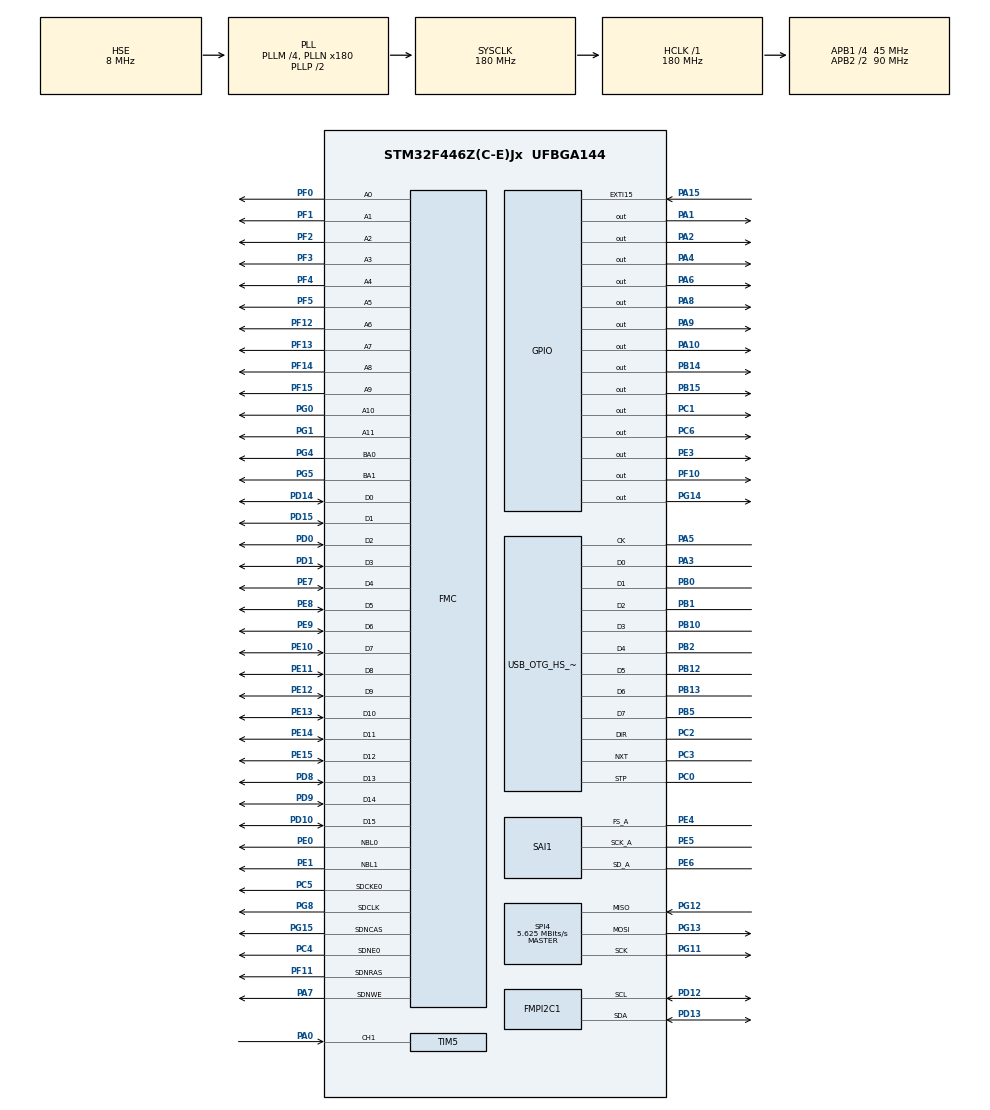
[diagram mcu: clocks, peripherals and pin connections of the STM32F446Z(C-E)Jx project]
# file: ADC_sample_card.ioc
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Dma.Request0=SAI1_A
Dma.SAI1_A.0.Direction=DMA_PERIPH_TO_MEMORY
Dma.SAI1_A.0.FIFOMode=DMA_FIFOMODE_DISABLE
Dma.SAI1_A.0.Instance=DMA2_Stream1
Dma.SAI1_A.0.MemDataAlignment=DMA_MDATAALIGN_WORD
Dma.SAI1_A.0.MemInc=DMA_MINC_ENABLE
Dma.SAI1_A.0.Mode=DMA_CIRCULAR
Dma.SAI1_A.0.PeriphDataAlignment=DMA_PDATAALIGN_WORD
Dma.SAI1_A.0.PeriphInc=DMA_PINC_DISABLE
Dma.SAI1_A.0.Priority=DMA_PRIORITY_LOW
FMC.CASLatency2=FMC_SDRAM_CAS_LATENCY_3
FMC.ExitSelfRefreshDelay2=7
FMC.LoadToActiveDelay2=2
FMC.RCDDelay2=2
FMC.RPDelay1=2
FMC.RPDelay2=2
FMC.ReadPipeDelay1=FMC_SDRAM_RPIPE_DELAY_1
FMC.ReadPipeDelay2=FMC_SDRAM_RPIPE_DELAY_1
FMC.RowCycleDelay1=7
FMC.RowCycleDelay2=7
FMC.SDClockPeriod1=FMC_SDRAM_CLOCK_PERIOD_3
FMC.SDClockPeriod2=FMC_SDRAM_CLOCK_PERIOD_3
FMC.SelfRefreshTime2=4
FMC.WriteRecoveryTime2=3
FMPI2C1.FMPI2C_Coeff_DF=5
FMPI2C1.Speed=100
FMPI2C1.Timing=0x20303955
FREERTOS.BinarySemaphores01=CommandSem,Dynamic,NULL
FREERTOS.Queues01=QueueTx,2,uint16_t,0,Dynamic,NULL,NULL
FREERTOS.Tasks01=defaultTask,0,128,StartDefaultTask,Default,NULL,Dynamic,NULL,NULL;usbTask,-3,128,UsbTask,Default,NULL,Dynamic,NULL,NULL
FREERTOS.configTOTAL_HEAP_SIZE=4096
Mcu.Family=STM32F4
Mcu.Name=STM32F446Z(C-E)Jx
Mcu.Package=UFBGA144
NVIC.DMA2_Stream1_IRQn=true\:5\:0\:false\:false\:true\:true\:false\:true
NVIC.EXTI15_10_IRQn=true\:5\:0\:false\:false\:true\:true\:true\:true
NVIC.OTG_HS_IRQn=true\:5\:0\:false\:false\:true\:true\:false\:true
NVIC.PriorityGroup=NVIC_PRIORITYGROUP_4
NVIC.SAI1_IRQn=true\:5\:0\:false\:false\:true\:true\:true\:true
NVIC.TIM6_DAC_IRQn=true\:0\:0\:false\:false\:true\:false\:false\:true
NVIC.TimeBase=TIM6_DAC_IRQn
NVIC.TimeBaseIP=TIM6
PA0-WKUP.Signal=S_TIM5_CH1
PA1.Signal=GPIO_Output
PA10.Signal=GPIO_Output
PA13.Mode=Serial_Wire
PA13.Signal=SYS_JTMS-SWDIO
PA14.Mode=Serial_Wire
PA14.Signal=SYS_JTCK-SWCLK
PA15.GPIO_ModeDefaultEXTI=GPIO_MODE_IT_RISING
PA15.Signal=GPXTI15
PA2.Signal=GPIO_Output
PA3.Mode=Device_HS
PA3.Signal=USB_OTG_HS_ULPI_D0
PA4.Signal=GPIO_Output
PA5.Mode=Device_HS
PA5.Signal=USB_OTG_HS_ULPI_CK
PA6.Signal=GPIO_Output
PA7.Signal=FMC_SDNWE
PA8.Signal=GPIO_Output
PA9.Signal=GPIO_Output
PB0.Mode=Device_HS
PB0.Signal=USB_OTG_HS_ULPI_D1
PB1.Mode=Device_HS
PB1.Signal=USB_OTG_HS_ULPI_D2
PB10.Mode=Device_HS
PB10.Signal=USB_OTG_HS_ULPI_D3
PB12.Mode=Device_HS
PB12.Signal=USB_OTG_HS_ULPI_D5
PB13.Mode=Device_HS
PB13.Signal=USB_OTG_HS_ULPI_D6
PB14.Signal=GPIO_Output
PB15.PinState=GPIO_PIN_SET
PB15.Signal=GPIO_Output
PB2.Mode=Device_HS
PB2.Signal=USB_OTG_HS_ULPI_D4
PB5.Mode=Device_HS
PB5.Signal=USB_OTG_HS_ULPI_D7
PC0.Mode=Device_HS
PC0.Signal=USB_OTG_HS_ULPI_STP
PC1.Signal=GPIO_Output
PC2.Mode=Device_HS
PC2.Signal=USB_OTG_HS_ULPI_DIR
PC3.Mode=Device_HS
PC3.Signal=USB_OTG_HS_ULPI_NXT
PC4.Mode=SdramChipSelect1_2
PC4.Signal=FMC_SDNE0
PC5.Mode=SdramChipSelect1_2
PC5.Signal=FMC_SDCKE0
PC6.PinState=GPIO_PIN_SET
PC6.Signal=GPIO_Output
PD0.Signal=FMC_D2_DA2
PD1.Signal=FMC_D3_DA3
PD10.Signal=FMC_D15_DA15
PD12.Mode=I2C
PD12.Signal=FMPI2C1_SCL
PD13.Mode=I2C
PD13.Signal=FMPI2C1_SDA
PD14.Signal=FMC_D0_DA0
PD15.Signal=FMC_D1_DA1
PD8.Signal=FMC_D13_DA13
PD9.Signal=FMC_D14_DA14
PE0.Signal=FMC_NBL0
PE1.Signal=FMC_NBL1
PE10.Signal=FMC_D7_DA7
PE11.Signal=FMC_D8_DA8
PE12.Signal=FMC_D9_DA9
PE13.Signal=FMC_D10_DA10
PE14.Signal=FMC_D11_DA11
PE15.Signal=FMC_D12_DA12
PE3.PinState=GPIO_PIN_SET
PE3.Signal=GPIO_Output
PE4.GPIO_Speed=GPIO_SPEED_FREQ_HIGH
PE4.Mode=SAI_A_AsyncSlave
PE4.Signal=SAI1_FS_A
PE5.GPIO_Speed=GPIO_SPEED_FREQ_HIGH
PE5.Mode=SAI_A_AsyncSlave
PE5.Signal=SAI1_SCK_A
PE6.GPIO_Speed=GPIO_SPEED_FREQ_HIGH
PE6.Mode=SAI_A_AsyncSlave
PE6.Signal=SAI1_SD_A
PE7.Signal=FMC_D4_DA4
PE8.Signal=FMC_D5_DA5
PE9.Signal=FMC_D6_DA6
PF0.Signal=FMC_A0
PF1.Signal=FMC_A1
PF10.GPIO_ModeDefaultOutputPP=GPIO_MODE_OUTPUT_PP
PF10.GPIO_PuPd=GPIO_NOPULL
PF10.GPIO_Speed=GPIO_SPEED_FREQ_LOW
PF10.PinState=GPIO_PIN_RESET
PF10.Signal=GPIO_Output
PF11.Signal=FMC_SDNRAS
PF12.Signal=FMC_A6
PF13.Signal=FMC_A7
PF14.Signal=FMC_A8
PF15.Signal=FMC_A9
PF2.Signal=FMC_A2
PF3.Signal=FMC_A3
PF4.Signal=FMC_A4
PF5.Signal=FMC_A5
PG0.Signal=FMC_A10
PG1.Signal=FMC_A11
PG11.Mode=Full_Duplex_Master
PG11.Signal=SPI4_SCK
PG12.Mode=Full_Duplex_Master
PG12.Signal=SPI4_MISO
PG13.Mode=Full_Duplex_Master
PG13.Signal=SPI4_MOSI
PG14.PinState=GPIO_PIN_SET
PG14.Signal=GPIO_Output
PG15.Signal=FMC_SDNCAS
PG4.Signal=FMC_A14_BA0
PG5.Signal=FMC_A15_BA1
PG8.Signal=FMC_SDCLK
PH0-OSC_IN.Mode=HSE-External-Oscillator
PH0-OSC_IN.Signal=RCC_OSC_IN
PH1-OSC_OUT.Mode=HSE-External-Oscillator
PH1-OSC_OUT.Signal=RCC_OSC_OUT
ProjectManager.HeapSize=0x600
ProjectManager.StackSize=0x900
ProjectManager.TargetToolchain=MDK-ARM V5
RCC.AHBFreq_Value=180000000
RCC.APB1CLKDivider=RCC_HCLK_DIV4
RCC.APB1Freq_Value=45000000
RCC.APB1TimFreq_Value=90000000
RCC.APB2CLKDivider=RCC_HCLK_DIV2
RCC.APB2Freq_Value=90000000
RCC.APB2TimFreq_Value=180000000
RCC.CortexFreq_Value=180000000
RCC.HCLKFreq_Value=180000000
RCC.HSE_VALUE=8000000
RCC.PLLM=4
RCC.PLLN=180
RCC.PLLSAIM=4
RCC.PLLSAIN=50
RCC.PLLSourceVirtual=RCC_PLLSOURCE_HSE
RCC.SYSCLKFreq_VALUE=180000000
RCC.SYSCLKSource=RCC_SYSCLKSOURCE_PLLCLK
RCC.USBFreq_Value=180000000
RCC.VCOOutputFreq_Value=360000000
SAI1.ClockStrobing-SAI_A_AsyncSlave=SAI_CLOCKSTROBING_RISINGEDGE
SAI1.DataSize-SAI_A_AsyncSlave=SAI_DATASIZE_32
SAI1.FIFOThreshold-SAI_A_AsyncSlave=SAI_FIFOTHRESHOLD_FULL
SAI1.FSOffset-SAI_A_AsyncSlave=SAI_FS_FIRSTBIT
SAI1.FrameLength-SAI_A_AsyncSlave=128
SAI1.Instance-SAI_A_AsyncSlave=SAI$Index_Block_A
SAI1.OutputDrive-SAI_A_AsyncSlave=SAI_OUTPUTDRIVE_DISABLE
SAI1.Protocol-SAI_A_AsyncSlave=SAI_FREE_PROTOCOL
SAI1.SlotActive-SAI_A_AsyncSlave=0x0000FFFF
SAI1.SlotNumber-SAI_A_AsyncSlave=4
SAI1.TriState-SAI_A_AsyncSlave=SAI_OUTPUT_RELEASED
SAI1.VirtualMode-SAI_A_AsyncSlave=VM_SLAVE
SAI1.VirtualSlotActive-SAI_A_AsyncSlave=SAI_SLOTACTIVE_ALL
SAI1.VirtualSlotActive0-SAI_A_AsyncSlave=false
SH.FMC_A0.0=FMC_A0,12b-sda2
SH.FMC_A1.0=FMC_A1,12b-sda2
SH.FMC_A10.0=FMC_A10,12b-sda2
SH.FMC_A11.0=FMC_A11,12b-sda2
SH.FMC_A14_BA0.0=FMC_BA0,FourSdramBanks2
SH.FMC_A15_BA1.0=FMC_BA1,FourSdramBanks2
SH.FMC_A2.0=FMC_A2,12b-sda2
SH.FMC_A3.0=FMC_A3,12b-sda2
SH.FMC_A4.0=FMC_A4,12b-sda2
SH.FMC_A5.0=FMC_A5,12b-sda2
SH.FMC_A6.0=FMC_A6,12b-sda2
SH.FMC_A7.0=FMC_A7,12b-sda2
SH.FMC_A8.0=FMC_A8,12b-sda2
SH.FMC_A9.0=FMC_A9,12b-sda2
SH.FMC_D0_DA0.0=FMC_D0,sd-16b-d2
SH.FMC_D10_DA10.0=FMC_D10,sd-16b-d2
SH.FMC_D11_DA11.0=FMC_D11,sd-16b-d2
SH.FMC_D12_DA12.0=FMC_D12,sd-16b-d2
SH.FMC_D13_DA13.0=FMC_D13,sd-16b-d2
SH.FMC_D14_DA14.0=FMC_D14,sd-16b-d2
SH.FMC_D15_DA15.0=FMC_D15,sd-16b-d2
SH.FMC_D1_DA1.0=FMC_D1,sd-16b-d2
SH.FMC_D2_DA2.0=FMC_D2,sd-16b-d2
SH.FMC_D3_DA3.0=FMC_D3,sd-16b-d2
SH.FMC_D4_DA4.0=FMC_D4,sd-16b-d2
SH.FMC_D5_DA5.0=FMC_D5,sd-16b-d2
SH.FMC_D6_DA6.0=FMC_D6,sd-16b-d2
SH.FMC_D7_DA7.0=FMC_D7,sd-16b-d2
SH.FMC_D8_DA8.0=FMC_D8,sd-16b-d2
SH.FMC_D9_DA9.0=FMC_D9,sd-16b-d2
SH.FMC_NBL0.0=FMC_NBL0,Sd2ByteEnable2
SH.FMC_NBL1.0=FMC_NBL1,Sd2ByteEnable2
SH.FMC_SDCLK.0=FMC_SDCLK,12b-sda2
SH.FMC_SDNCAS.0=FMC_SDNCAS,12b-sda2
SH.FMC_SDNRAS.0=FMC_SDNRAS,12b-sda2
SH.FMC_SDNWE.0=FMC_SDNWE,12b-sda2
SH.S_TIM5_CH1.0=TIM5_CH1,TriggerSource_TI1FP1
SPI4.BaudRatePrescaler=SPI_BAUDRATEPRESCALER_16
SPI4.CalculateBaudRate=5.625 MBits/s
SPI4.DataSize=SPI_DATASIZE_8BIT
SPI4.Direction=SPI_DIRECTION_2LINES
SPI4.Mode=SPI_MODE_MASTER
SPI4.VirtualType=VM_MASTER
TIM5.Period=65535
TIM5.Slave_TriggerFilter=1
USB_DEVICE.CLASS_NAME_HS=CDC
USB_DEVICE.VirtualMode-CDC_HS=Cdc
USB_DEVICE.VirtualModeHS=Cdc_HS
USB_OTG_HS.DeviceSpeed-Device_HS=PCD_SPEED_HIGH
USB_OTG_HS.VirtualMode-Device_HS=Device_HS
USB_OTG_HS.dma_enable-Device_HS=DISABLE
VP_FREERTOS_VS_CMSIS_V1.Mode=CMSIS_V1
VP_SYS_VS_tim6.Mode=TIM6
VP_TIM5_VS_ControllerModeClock.Mode=Clock Mode
VP_USB_DEVICE_VS_USB_DEVICE_CDC_HS.Mode=CDC_HS
board=custom

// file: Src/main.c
/* USER CODE BEGIN Header */
/**
  ******************************************************************************
  * @file           : main.c
  * @brief          : Main program body
  ******************************************************************************
  * @attention
  *
  * <h2><center>&copy; Copyright (c) 2019 STMicroelectronics.
  * All rights reserved.</center></h2>
  *
  * This software component is licensed by ST under Ultimate Liberty license
  * SLA0044, the "License"; You may not use this file except in compliance with
  * the License. You may obtain a copy of the License at:
  *                             www.st.com/SLA0044
  *
  ******************************************************************************
  */
/* USER CODE END Header */

#include "main.h"
#include "cmsis_os.h"
#include "usb_device.h"

/* USER CODE BEGIN Includes */
#include "CDCEL913.h"
#include "ad7768.h"
#include "command.h"
#include "usbd_cdc_if.h"
#include "sdram.h"
/* USER CODE END Includes */

FMPI2C_HandleTypeDef hfmpi2c1;

SAI_HandleTypeDef hsai_BlockA1;
DMA_HandleTypeDef hdma_sai1_a;

SPI_HandleTypeDef hspi4;

TIM_HandleTypeDef htim5;

SDRAM_HandleTypeDef hsdram2;

osThreadId defaultTaskHandle;
osThreadId usbTaskHandle;
osMessageQId QueueTxHandle;
osSemaphoreId CommandSemHandle;

void SystemClock_Config(void);
static void MX_GPIO_Init(void);
static void MX_DMA_Init(void);
static void MX_FMPI2C1_Init(void);
static void MX_SPI4_Init(void);
static void MX_SAI1_Init(void);
static void MX_FMC_Init(void);
static void MX_TIM5_Init(void);
void StartDefaultTask(void const * argument);
void UsbTask(void const * argument);

/* USER CODE BEGIN PFP */
FMC_SDRAM_CommandTypeDef command;

uint16_t digital_cnt = 0;
uint32_t digital_clk[256];
/* USER CODE END PFP */

int main(void)
{

  /* MCU Configuration--------------------------------------------------------*/

  /* Reset of all peripherals, Initializes the Flash interface and the Systick. */
  HAL_Init();

  /* Configure the system clock */
  SystemClock_Config();

  /* Initialize all configured peripherals */
  MX_GPIO_Init();
  MX_DMA_Init();
  MX_FMPI2C1_Init();
  MX_SPI4_Init();
  MX_SAI1_Init();
  MX_FMC_Init();
  MX_TIM5_Init();
  /* USER CODE BEGIN 2 */
	SDRAM_Initialization_Sequence(&hsdram2, &command);
  /* USER CODE END 2 */

  /* Create the semaphores(s) */
  /* definition and creation of CommandSem */
  osSemaphoreDef(CommandSem);
  CommandSemHandle = osSemaphoreCreate(osSemaphore(CommandSem), 1);

  /* Create the queue(s) */
  /* definition and creation of QueueTx */
  osMessageQDef(QueueTx, 2, uint16_t);
  QueueTxHandle = osMessageCreate(osMessageQ(QueueTx), NULL);

  /* Create the thread(s) */
  /* definition and creation of defaultTask */
  osThreadDef(defaultTask, StartDefaultTask, osPriorityNormal, 0, 128);
  defaultTaskHandle = osThreadCreate(osThread(defaultTask), NULL);

  /* definition and creation of usbTask */
  osThreadDef(usbTask, UsbTask, osPriorityIdle, 0, 128);
  usbTaskHandle = osThreadCreate(osThread(usbTask), NULL);

  /* Start scheduler */
  osKernelStart();

  /* We should never get here as control is now taken by the scheduler */
  /* Infinite loop */
  while (1)
  {

  }
}

void SystemClock_Config(void)
{
  RCC_OscInitTypeDef RCC_OscInitStruct = {0};
  RCC_ClkInitTypeDef RCC_ClkInitStruct = {0};
  RCC_PeriphCLKInitTypeDef PeriphClkInitStruct = {0};

  /** Configure the main internal regulator output voltage
  */
  __HAL_RCC_PWR_CLK_ENABLE();
  __HAL_PWR_VOLTAGESCALING_CONFIG(PWR_REGULATOR_VOLTAGE_SCALE1);
  /** Initializes the CPU, AHB and APB busses clocks
  */
  RCC_OscInitStruct.OscillatorType = RCC_OSCILLATORTYPE_HSE;
  RCC_OscInitStruct.HSEState = RCC_HSE_ON;
  RCC_OscInitStruct.PLL.PLLState = RCC_PLL_ON;
  RCC_OscInitStruct.PLL.PLLSource = RCC_PLLSOURCE_HSE;
  RCC_OscInitStruct.PLL.PLLM = 4;
  RCC_OscInitStruct.PLL.PLLN = 180;
  RCC_OscInitStruct.PLL.PLLP = RCC_PLLP_DIV2;
  RCC_OscInitStruct.PLL.PLLQ = 2;
  RCC_OscInitStruct.PLL.PLLR = 2;
  if (HAL_RCC_OscConfig(&RCC_OscInitStruct) != HAL_OK)
  {
    Error_Handler();
  }
  /** Activate the Over-Drive mode
  */
  if (HAL_PWREx_EnableOverDrive() != HAL_OK)
  {
    Error_Handler();
  }
  /** Initializes the CPU, AHB and APB busses clocks
  */
  RCC_ClkInitStruct.ClockType = RCC_CLOCKTYPE_HCLK|RCC_CLOCKTYPE_SYSCLK
                              |RCC_CLOCKTYPE_PCLK1|RCC_CLOCKTYPE_PCLK2;
  RCC_ClkInitStruct.SYSCLKSource = RCC_SYSCLKSOURCE_PLLCLK;
  RCC_ClkInitStruct.AHBCLKDivider = RCC_SYSCLK_DIV1;
  RCC_ClkInitStruct.APB1CLKDivider = RCC_HCLK_DIV4;
  RCC_ClkInitStruct.APB2CLKDivider = RCC_HCLK_DIV2;

  if (HAL_RCC_ClockConfig(&RCC_ClkInitStruct, FLASH_LATENCY_5) != HAL_OK)
  {
    Error_Handler();
  }
  PeriphClkInitStruct.PeriphClockSelection = RCC_PERIPHCLK_SAI1|RCC_PERIPHCLK_FMPI2C1;
  PeriphClkInitStruct.PLLSAI.PLLSAIM = 4;
  PeriphClkInitStruct.PLLSAI.PLLSAIN = 50;
  PeriphClkInitStruct.PLLSAI.PLLSAIQ = 2;
  PeriphClkInitStruct.PLLSAI.PLLSAIP = RCC_PLLSAIP_DIV2;
  PeriphClkInitStruct.PLLSAIDivQ = 1;
  PeriphClkInitStruct.Sai1ClockSelection = RCC_SAI1CLKSOURCE_PLLSAI;
  PeriphClkInitStruct.Fmpi2c1ClockSelection = RCC_FMPI2C1CLKSOURCE_APB;
  if (HAL_RCCEx_PeriphCLKConfig(&PeriphClkInitStruct) != HAL_OK)
  {
    Error_Handler();
  }
}

static void MX_FMPI2C1_Init(void)
{

  hfmpi2c1.Instance = FMPI2C1;
  hfmpi2c1.Init.Timing = 0x20303955;
  hfmpi2c1.Init.OwnAddress1 = 0;
  hfmpi2c1.Init.AddressingMode = FMPI2C_ADDRESSINGMODE_7BIT;
  hfmpi2c1.Init.DualAddressMode = FMPI2C_DUALADDRESS_DISABLE;
  hfmpi2c1.Init.OwnAddress2 = 0;
  hfmpi2c1.Init.OwnAddress2Masks = FMPI2C_OA2_NOMASK;
  hfmpi2c1.Init.GeneralCallMode = FMPI2C_GENERALCALL_DISABLE;
  hfmpi2c1.Init.NoStretchMode = FMPI2C_NOSTRETCH_DISABLE;
  if (HAL_FMPI2C_Init(&hfmpi2c1) != HAL_OK)
  {
    Error_Handler();
  }
  /** Configure Analogue filter
  */
  if (HAL_FMPI2CEx_ConfigAnalogFilter(&hfmpi2c1, FMPI2C_ANALOGFILTER_ENABLE) != HAL_OK)
  {
    Error_Handler();
  }

}

static void MX_SAI1_Init(void)
{

  hsai_BlockA1.Instance = SAI1_Block_A;
  hsai_BlockA1.Init.Protocol = SAI_FREE_PROTOCOL;
  hsai_BlockA1.Init.AudioMode = SAI_MODESLAVE_RX;
  hsai_BlockA1.Init.DataSize = SAI_DATASIZE_32;
  hsai_BlockA1.Init.FirstBit = SAI_FIRSTBIT_MSB;
  hsai_BlockA1.Init.ClockStrobing = SAI_CLOCKSTROBING_RISINGEDGE;
  hsai_BlockA1.Init.Synchro = SAI_ASYNCHRONOUS;
  hsai_BlockA1.Init.OutputDrive = SAI_OUTPUTDRIVE_DISABLE;
  hsai_BlockA1.Init.FIFOThreshold = SAI_FIFOTHRESHOLD_FULL;
  hsai_BlockA1.Init.SynchroExt = SAI_SYNCEXT_DISABLE;
  hsai_BlockA1.Init.MonoStereoMode = SAI_STEREOMODE;
  hsai_BlockA1.Init.CompandingMode = SAI_NOCOMPANDING;
  hsai_BlockA1.Init.TriState = SAI_OUTPUT_RELEASED;
  hsai_BlockA1.FrameInit.FrameLength = 128;
  hsai_BlockA1.FrameInit.ActiveFrameLength = 1;
  hsai_BlockA1.FrameInit.FSDefinition = SAI_FS_STARTFRAME;
  hsai_BlockA1.FrameInit.FSPolarity = SAI_FS_ACTIVE_LOW;
  hsai_BlockA1.FrameInit.FSOffset = SAI_FS_FIRSTBIT;
  hsai_BlockA1.SlotInit.FirstBitOffset = 0;
  hsai_BlockA1.SlotInit.SlotSize = SAI_SLOTSIZE_DATASIZE;
  hsai_BlockA1.SlotInit.SlotNumber = 4;
  hsai_BlockA1.SlotInit.SlotActive = 0x0000FFFF;
  if (HAL_SAI_Init(&hsai_BlockA1) != HAL_OK)
  {
    Error_Handler();
  }

}

static void MX_SPI4_Init(void)
{

  /* SPI4 parameter configuration*/
  hspi4.Instance = SPI4;
  hspi4.Init.Mode = SPI_MODE_MASTER;
  hspi4.Init.Direction = SPI_DIRECTION_2LINES;
  hspi4.Init.DataSize = SPI_DATASIZE_8BIT;
  hspi4.Init.CLKPolarity = SPI_POLARITY_LOW;
  hspi4.Init.CLKPhase = SPI_PHASE_1EDGE;
  hspi4.Init.NSS = SPI_NSS_SOFT;
  hspi4.Init.BaudRatePrescaler = SPI_BAUDRATEPRESCALER_16;
  hspi4.Init.FirstBit = SPI_FIRSTBIT_MSB;
  hspi4.Init.TIMode = SPI_TIMODE_DISABLE;
  hspi4.Init.CRCCalculation = SPI_CRCCALCULATION_DISABLE;
  hspi4.Init.CRCPolynomial = 10;
  if (HAL_SPI_Init(&hspi4) != HAL_OK)
  {
    Error_Handler();
  }

}

static void MX_TIM5_Init(void)
{

  TIM_SlaveConfigTypeDef sSlaveConfig = {0};
  TIM_MasterConfigTypeDef sMasterConfig = {0};

  htim5.Instance = TIM5;
  htim5.Init.Prescaler = 0;
  htim5.Init.CounterMode = TIM_COUNTERMODE_UP;
  htim5.Init.Period = 65535;
  htim5.Init.ClockDivision = TIM_CLOCKDIVISION_DIV1;
  htim5.Init.AutoReloadPreload = TIM_AUTORELOAD_PRELOAD_DISABLE;
  if (HAL_TIM_Base_Init(&htim5) != HAL_OK)
  {
    Error_Handler();
  }
  sSlaveConfig.SlaveMode = TIM_SLAVEMODE_EXTERNAL1;
  sSlaveConfig.InputTrigger = TIM_TS_TI1FP1;
  sSlaveConfig.TriggerPolarity = TIM_TRIGGERPOLARITY_RISING;
  sSlaveConfig.TriggerFilter = 1;
  if (HAL_TIM_SlaveConfigSynchro(&htim5, &sSlaveConfig) != HAL_OK)
  {
    Error_Handler();
  }
  sMasterConfig.MasterOutputTrigger = TIM_TRGO_RESET;
  sMasterConfig.MasterSlaveMode = TIM_MASTERSLAVEMODE_DISABLE;
  if (HAL_TIMEx_MasterConfigSynchronization(&htim5, &sMasterConfig) != HAL_OK)
  {
    Error_Handler();
  }

}

static void MX_DMA_Init(void)
{

  /* DMA controller clock enable */
  __HAL_RCC_DMA2_CLK_ENABLE();

  /* DMA interrupt init */
  /* DMA2_Stream1_IRQn interrupt configuration */
  HAL_NVIC_SetPriority(DMA2_Stream1_IRQn, 5, 0);
  HAL_NVIC_EnableIRQ(DMA2_Stream1_IRQn);

}

/* FMC initialization function */
static void MX_FMC_Init(void)
{

  FMC_SDRAM_TimingTypeDef SdramTiming = {0};

  /** Perform the SDRAM2 memory initialization sequence
  */
  hsdram2.Instance = FMC_SDRAM_DEVICE;
  /* hsdram2.Init */
  hsdram2.Init.SDBank = FMC_SDRAM_BANK2;
  hsdram2.Init.ColumnBitsNumber = FMC_SDRAM_COLUMN_BITS_NUM_8;
  hsdram2.Init.RowBitsNumber = FMC_SDRAM_ROW_BITS_NUM_12;
  hsdram2.Init.MemoryDataWidth = FMC_SDRAM_MEM_BUS_WIDTH_16;
  hsdram2.Init.InternalBankNumber = FMC_SDRAM_INTERN_BANKS_NUM_4;
  hsdram2.Init.CASLatency = FMC_SDRAM_CAS_LATENCY_3;
  hsdram2.Init.WriteProtection = FMC_SDRAM_WRITE_PROTECTION_DISABLE;
  hsdram2.Init.SDClockPeriod = FMC_SDRAM_CLOCK_PERIOD_3;
  hsdram2.Init.ReadBurst = FMC_SDRAM_RBURST_DISABLE;
  hsdram2.Init.ReadPipeDelay = FMC_SDRAM_RPIPE_DELAY_1;
  /* SdramTiming */
  SdramTiming.LoadToActiveDelay = 2;
  SdramTiming.ExitSelfRefreshDelay = 7;
  SdramTiming.SelfRefreshTime = 4;
  SdramTiming.RowCycleDelay = 7;
  SdramTiming.WriteRecoveryTime = 3;
  SdramTiming.RPDelay = 2;
  SdramTiming.RCDDelay = 2;

  if (HAL_SDRAM_Init(&hsdram2, &SdramTiming) != HAL_OK)
  {
    Error_Handler( );
  }

}

static void MX_GPIO_Init(void)
{
  GPIO_InitTypeDef GPIO_InitStruct = {0};

  /* GPIO Ports Clock Enable */
  __HAL_RCC_GPIOE_CLK_ENABLE();
  __HAL_RCC_GPIOA_CLK_ENABLE();
  __HAL_RCC_GPIOB_CLK_ENABLE();
  __HAL_RCC_GPIOG_CLK_ENABLE();
  __HAL_RCC_GPIOF_CLK_ENABLE();
  __HAL_RCC_GPIOH_CLK_ENABLE();
  __HAL_RCC_GPIOD_CLK_ENABLE();
  __HAL_RCC_GPIOC_CLK_ENABLE();

  /*Configure GPIO pin Output Level */
  HAL_GPIO_WritePin(GPIOE, GPIO_PIN_3, GPIO_PIN_SET);

  /*Configure GPIO pin Output Level */
  HAL_GPIO_WritePin(GPIOG, GPIO_PIN_14, GPIO_PIN_SET);

  /*Configure GPIO pin Output Level */
  HAL_GPIO_WritePin(GPIOA, GPIO_PIN_10|GPIO_PIN_9|GPIO_PIN_8|GPIO_PIN_4
                          |GPIO_PIN_1|GPIO_PIN_2|GPIO_PIN_6, GPIO_PIN_RESET);

  /*Configure GPIO pin Output Level */
  HAL_GPIO_WritePin(GPIOF, GPIO_PIN_10, GPIO_PIN_RESET);

  /*Configure GPIO pin Output Level */
  HAL_GPIO_WritePin(GPIOC, GPIO_PIN_6, GPIO_PIN_SET);

  /*Configure GPIO pin Output Level */
  HAL_GPIO_WritePin(GPIOC, GPIO_PIN_1, GPIO_PIN_RESET);

  /*Configure GPIO pin Output Level */
  HAL_GPIO_WritePin(GPIOB, GPIO_PIN_14, GPIO_PIN_RESET);

  /*Configure GPIO pin Output Level */
  HAL_GPIO_WritePin(GPIOB, GPIO_PIN_15, GPIO_PIN_SET);

  /*Configure GPIO pin : PE3 */
  GPIO_InitStruct.Pin = GPIO_PIN_3;
  GPIO_InitStruct.Mode = GPIO_MODE_OUTPUT_PP;
  GPIO_InitStruct.Pull = GPIO_NOPULL;
  GPIO_InitStruct.Speed = GPIO_SPEED_FREQ_LOW;
  HAL_GPIO_Init(GPIOE, &GPIO_InitStruct);

  /*Configure GPIO pin : PA15 */
  GPIO_InitStruct.Pin = GPIO_PIN_15;
  GPIO_InitStruct.Mode = GPIO_MODE_IT_RISING;
  GPIO_InitStruct.Pull = GPIO_NOPULL;
  HAL_GPIO_Init(GPIOA, &GPIO_InitStruct);

  /*Configure GPIO pin : PG14 */
  GPIO_InitStruct.Pin = GPIO_PIN_14;
  GPIO_InitStruct.Mode = GPIO_MODE_OUTPUT_PP;
  GPIO_InitStruct.Pull = GPIO_NOPULL;
  GPIO_InitStruct.Speed = GPIO_SPEED_FREQ_LOW;
  HAL_GPIO_Init(GPIOG, &GPIO_InitStruct);

  /*Configure GPIO pins : PA10 PA9 PA8 PA4
                           PA1 PA2 PA6 */
  GPIO_InitStruct.Pin = GPIO_PIN_10|GPIO_PIN_9|GPIO_PIN_8|GPIO_PIN_4
                          |GPIO_PIN_1|GPIO_PIN_2|GPIO_PIN_6;
  GPIO_InitStruct.Mode = GPIO_MODE_OUTPUT_PP;
  GPIO_InitStruct.Pull = GPIO_NOPULL;
  GPIO_InitStruct.Speed = GPIO_SPEED_FREQ_LOW;
  HAL_GPIO_Init(GPIOA, &GPIO_InitStruct);

  /*Configure GPIO pin : PF10 */
  GPIO_InitStruct.Pin = GPIO_PIN_10;
  GPIO_InitStruct.Mode = GPIO_MODE_OUTPUT_PP;
  GPIO_InitStruct.Pull = GPIO_NOPULL;
  GPIO_InitStruct.Speed = GPIO_SPEED_FREQ_LOW;
  HAL_GPIO_Init(GPIOF, &GPIO_InitStruct);

  /*Configure GPIO pins : PC6 PC1 */
  GPIO_InitStruct.Pin = GPIO_PIN_6|GPIO_PIN_1;
  GPIO_InitStruct.Mode = GPIO_MODE_OUTPUT_PP;
  GPIO_InitStruct.Pull = GPIO_NOPULL;
  GPIO_InitStruct.Speed = GPIO_SPEED_FREQ_LOW;
  HAL_GPIO_Init(GPIOC, &GPIO_InitStruct);

  /*Configure GPIO pins : PB14 PB15 */
  GPIO_InitStruct.Pin = GPIO_PIN_14|GPIO_PIN_15;
  GPIO_InitStruct.Mode = GPIO_MODE_OUTPUT_PP;
  GPIO_InitStruct.Pull = GPIO_NOPULL;
  GPIO_InitStruct.Speed = GPIO_SPEED_FREQ_LOW;
  HAL_GPIO_Init(GPIOB, &GPIO_InitStruct);

  /* EXTI interrupt init*/
  HAL_NVIC_SetPriority(EXTI15_10_IRQn, 5, 0);
//  HAL_NVIC_EnableIRQ(EXTI15_10_IRQn);

}

void StartDefaultTask(void const * argument)
{
  /* init code for USB_DEVICE */
  MX_USB_DEVICE_Init();
  /* USER CODE BEGIN 5 */
	CDCEL913_Config();

	sdram_test();

	//clock select
//	HAL_GPIO_WritePin(GPIOB, GPIO_PIN_14, (GPIO_PinState)1);

	ad7768_setup();
	digital_trig_set();
  /* Infinite loop */
  for(;;)
  {
		osSemaphoreWait(CommandSemHandle, 0xffffffff);
		if(CDC_Buf && CDC_Len)
		{
			CMD_Process(CDC_Buf, CDC_Len);
			CDC_Buf = 0;
			CDC_Len = 0;
		}
  }
  /* USER CODE END 5 */
}

/* USER CODE BEGIN Header_UsbTask */
/**
* @brief Function implementing the usbTask thread.
* @param argument: Not used
* @retval None
*/

extern uint32_t sai_data[1024];
uint32_t data_send[512];
/* USER CODE END Header_UsbTask */
void UsbTask(void const * argument)
{
  /* USER CODE BEGIN UsbTask */
	uint16_t i,j,k;
	uint8_t a = 0;
	uint32_t value;
	osEvent event;
  /* Infinite loop */
  for(;;)
  {
		event = osMessageGet(QueueTxHandle, 0xffffffff);
		if(event.status == osEventMessage)
		{
			value = event.value.v;
			j = 0, k = 0;

			for(i=0; i<ad7768_device.data_block_size; i++)
			{
				data_send[j++] = sai_data[value + i];
				if(++a == 4)
				{
					data_send[j++] = digital_clk[k++];
					a = 0;
				}
//				if(i<digital_cnt)
//				{
//					sai_data[value+i+ad7768_device.data_block_size] = digital_clk[i] = 0;[i];
//				}
//				else
//				{
//					sai_data[value+i+ad7768_device.data_block_size] = 0;
//				}
			}

			digital_cnt = 0;
			for(i=0; i<256; i++)
			{
				digital_clk[i] = 0;
			}

			CDC_Transmit_HS((uint8_t *)data_send, ad7768_device.data_block_size*5);

		}
  }
  /* USER CODE END UsbTask */
}

 /**
  * @brief  Period elapsed callback in non blocking mode
  * @note   This function is called  when TIM6 interrupt took place, inside
  * HAL_TIM_IRQHandler(). It makes a direct call to HAL_IncTick() to increment
  * a global variable "uwTick" used as application time base.
  * @param  htim : TIM handle
  * @retval None
  */
void HAL_TIM_PeriodElapsedCallback(TIM_HandleTypeDef *htim)
{
  if (htim->Instance == TIM6) {
    HAL_IncTick();
  }
}

void Error_Handler(void)
{
}

/************************ (C) COPYRIGHT STMicroelectronics *****END OF FILE****/
